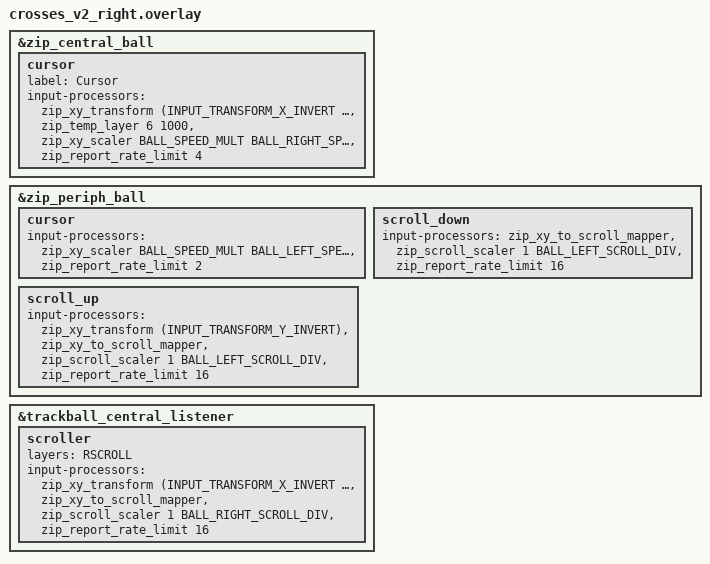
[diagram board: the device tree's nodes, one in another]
// Right (central) ball. Runs on the central via trackball_central_listener.
// Orientation = X+Y invert in every mode (matches prior cursor behavior).
// Scroll Down reuses orientation with Y un-inverted (net X invert), which
// is the opposite wheel direction from Scroll Up.

// Trackball speed: each ball moves at 1 / *_DIV of what the sensor reports,
// on top of the CPI set in Keystage. The scalers keep remainders, so slow
// movements aren't lost. The pipelines repeat the board's own processors
// (crosses-v2-zmk-firmware crosses_v2.dts) with the scalers changed. The left
// ball's pipelines run on the left half, so changing them needs both halves
// flashed.
#define BALL_SPEED_MULT 1
#define BALL_LEFT_SPEED_DIV 2
#define BALL_RIGHT_SPEED_DIV 2
// Scroll modes divide by 8 on the board; a higher number scrolls slower.
#define BALL_LEFT_SCROLL_DIV 32
#define BALL_RIGHT_SCROLL_DIV 64
#define RSCROLL 7

&zip_central_ball {
    cursor {
        label = "Cursor";
        input-processors
            = <&zip_xy_transform (INPUT_TRANSFORM_X_INVERT | INPUT_TRANSFORM_Y_INVERT)>
            , <&zip_temp_layer 6 1000>
            , <&zip_xy_scaler BALL_SPEED_MULT BALL_RIGHT_SPEED_DIV>
            , <&zip_report_rate_limit 4>;
    };
};

// The left ball's scroll directions are swapped from the board's: Scroll Up
// gets the Y invert that Scroll Down has there.
&zip_periph_ball {
    cursor {
        input-processors
          = <&zip_xy_scaler BALL_SPEED_MULT BALL_LEFT_SPEED_DIV>
          , <&zip_report_rate_limit 2>;
    };

    scroll_up {
        input-processors
          = <&zip_xy_transform (INPUT_TRANSFORM_Y_INVERT)>
          , <&zip_xy_to_scroll_mapper>
          , <&zip_scroll_scaler 1 BALL_LEFT_SCROLL_DIV>
          , <&zip_report_rate_limit 16>;
    };

    scroll_down {
        input-processors
          = <&zip_xy_to_scroll_mapper>
          , <&zip_scroll_scaler 1 BALL_LEFT_SCROLL_DIV>
          , <&zip_report_rate_limit 16>;
    };
};

// Right hand trackball listener configuration
&trackball_central_listener {
    // When layer 7 is active, it intercepts the input and applies scroll rules instead
    scroller {
        layers = <RSCROLL>; // Links directly to your scroll_layer index
        input-processors
            = <&zip_xy_transform (INPUT_TRANSFORM_X_INVERT | INPUT_TRANSFORM_Y_INVERT)>
            , <&zip_xy_to_scroll_mapper>
            , <&zip_scroll_scaler 1 BALL_RIGHT_SCROLL_DIV>
            , <&zip_report_rate_limit 16>;
    };
};
